# nrf5340_application register map
Vendor: Nordic Semiconductor; Series: nrf53; File version: 1
CPU: CM33 r0p4, little endian, MPU, FPU, 3 interrupt priority bits, 69 interrupts
Registers are 32-bit, read-write, reset 0x0 unless marked. A register's access mark holds for its fields unless they carry their own. Offsets are from the block's base; [hi:lo] are bit positions; lines under a group give offsets from that group.

## CTRLAP_NS — Control access port 0
Base 0x40006000
Same registers: CTRLAP_S 0x50006000
0x400 MAILBOX group — Unspecified
  0x00 RXDATA ro — Data sent from the debugger to the CPU.
    [31:0] RXDATA — Data received from debugger
  0x04 RXSTATUS ro — This register shows a status that indicates if data sent from the debugger to the CPU has been read.
    [0] RXSTATUS — Status of data in register RXDATA
      0=No data pending in register RXDATA; 1=Data pending in register RXDATA
  0x80 TXDATA — Data sent from the CPU to the debugger.
    [31:0] TXDATA — Data sent to debugger
  0x84 TXSTATUS ro — This register shows a status that indicates if the data sent from the CPU to the debugger has been read.
    [0] TXSTATUS — Status of data in register TXDATA
      0=No data pending in register TXDATA; 1=Data pending in register TXDATA
0x500 ERASEPROTECT group — Unspecified
  0x00 LOCK rw-once — This register locks the ERASEPROTECT.DISABLE register from being written until next reset.
    [0] LOCK — Lock ERASEPROTECT.DISABLE register from being written until next reset
      0=Unlocked (Register ERASEPROTECT.DISABLE is writeable); 1=Locked (Register ERASEPROTECT.DISABLE is read-only)
  0x04 DISABLE rw-once — This register disables the ERASEPROTECT register and performs an ERASEALL operation.
    [31:0] KEY — The ERASEALL sequence is initiated if the value of the KEY fields are non-zero and the KEY fields match on both the CPU and debugger sides.
0x540 APPROTECT group — Unspecified
  0x00 LOCK rw-once — This register locks the APPROTECT.DISABLE register from being written to until next reset.
    [0] LOCK — Lock the APPROTECT.DISABLE register from being written to until next reset
      0=Unlocked (Register APPROTECT.DISABLE is writeable); 1=Locked (Register APPROTECT.DISABLE is read-only)
  0x04 DISABLE — This register disables the APPROTECT register and enables debug access to non-secure mode.
    [31:0] KEY — If the value of the KEY field is non-zero, and the KEY fields match on both the CPU and debugger sides, disable APPROTECT and enable debug access to non-secure mode until the next pin reset, brown-out reset, power-on reset, or watchog timer reset. After reset the debugger side register has a fixed KEY value. To enable debug access, both CTRL-AP and UICR.APPROTECT protection needs to be disabled.
0x548 SECUREAPPROTECT group — Unspecified
  0x00 LOCK rw-once — This register locks the SECUREAPPROTECT.DISABLE register from being written until next reset.
    [0] LOCK — Lock register SECUREAPPROTECT.DISABLE from being written until next reset
      0=Unlocked (Register SECUREAPPROTECT.DISABLE is writeable); 1=Locked (Register SECUREAPPROTECT.DISABLE is read-only)
  0x04 DISABLE — This register disables the SECUREAPPROTECT register and enables debug access to secure mode.
    [31:0] KEY — If the value of the KEY field is non-zero, and the KEY fields match on both the CPU and debugger sides, disable SECUREAPPROTECT and enable debug access to secure mode until the next pin reset, brown-out reset, power-on reset, or watchog timer reset. After reset the debugger side register has a fixed KEY value. To enable debug access, both CTRL-AP and UICR.SECUREAPPROTECT protection needs to be disabled.
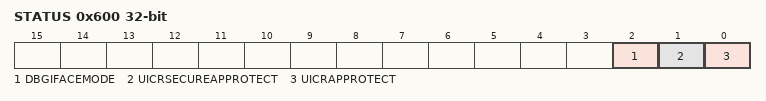
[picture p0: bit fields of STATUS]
0x600 STATUS ro — Status bits for CTRL-AP peripheral.
  [2] DBGIFACEMODE — Status bit for device debug interface mode
    0=Disabled (No debugger attached); 1=Enabled (Debugger is attached and device is in debug interface mode)
  [1] UICRSECUREAPPROTECT — Status bit for UICR part of secure access port protection at last reset.
    0=Enabled (SECUREAPPROTECT was enabled in UICR); 1=Disabled (SECUREAPPROTECT was disabled in UICR)
  [0] UICRAPPROTECT — Status bit for UICR part of access port protection at last reset.
    0=Enabled (APPROTECT was enabled in UICR); 1=Disabled (APPROTECT wasdisabled in UICR)
